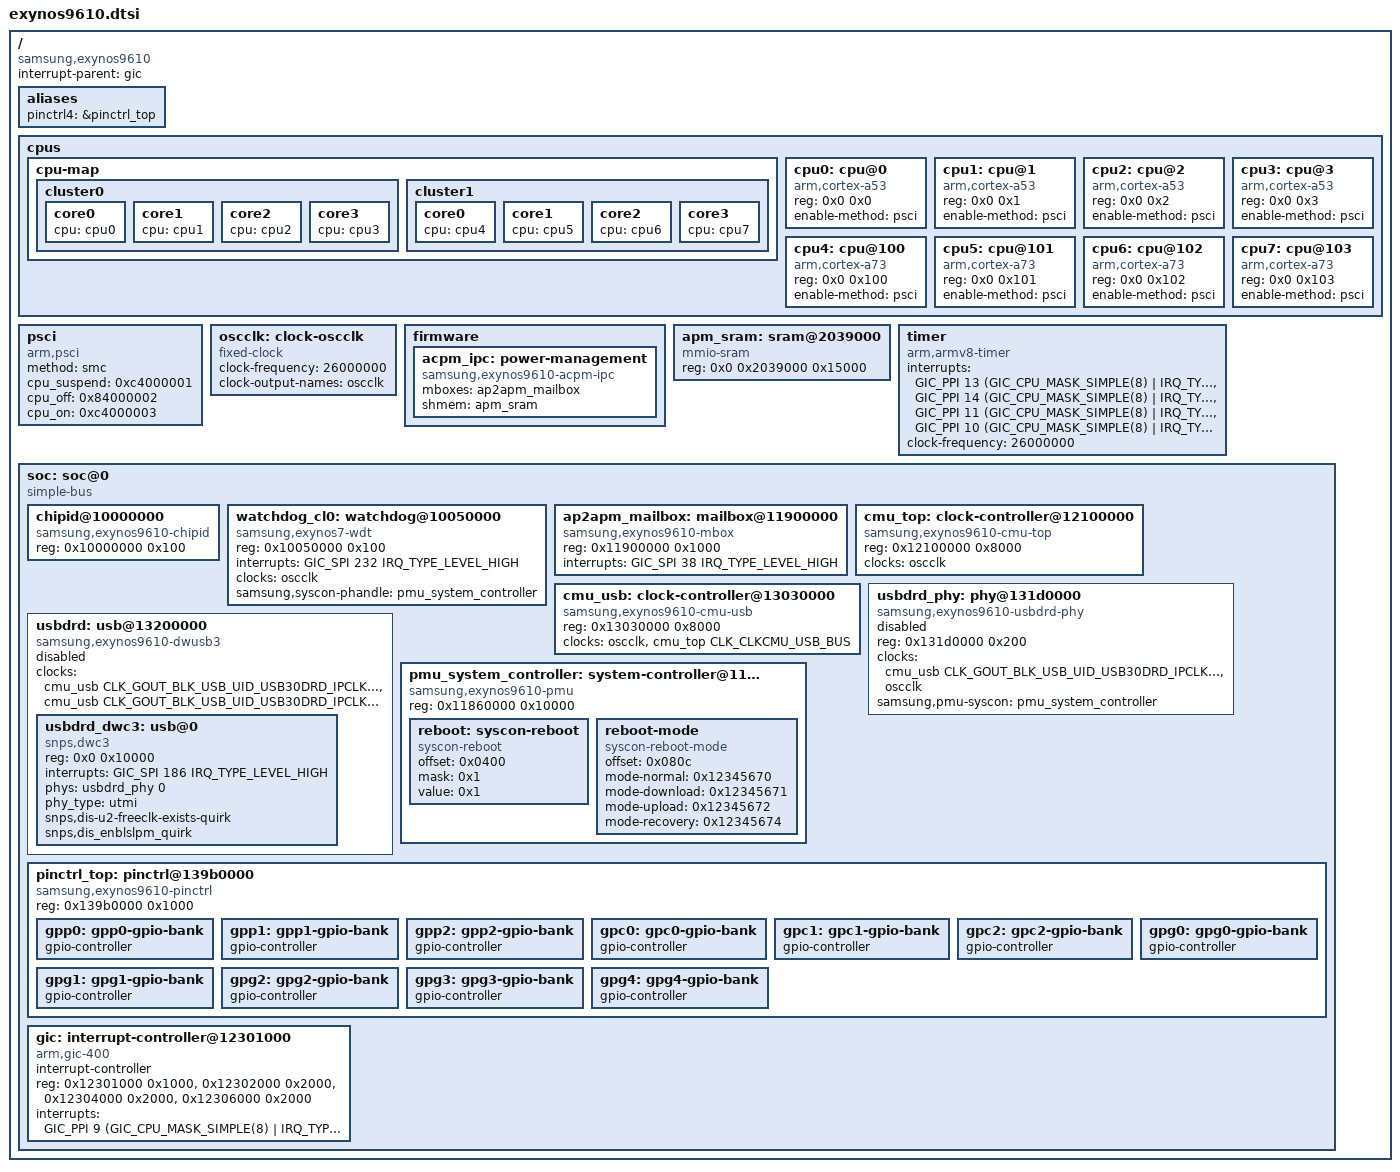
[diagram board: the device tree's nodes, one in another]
// SPDX-License-Identifier: GPL-2.0
/*
 * Samsung Exynos 9610 / 9611 SoC device tree source
 *
 * Early bring-up: CPUs, GIC, timer, PMU (reboot, reboot mode), the CPUCL0
 * watchdog (on the fixed 26 MHz OSCCLK) and USB with the CMU_TOP/CMU_USB
 * clocks it needs.
 */

#include <dt-bindings/clock/samsung,exynos9610-cmu.h>
#include <dt-bindings/interrupt-controller/arm-gic.h>

/ {
	compatible = "samsung,exynos9610";
	#address-cells = <2>;
	#size-cells = <1>;

	interrupt-parent = <&gic>;

	aliases {
		pinctrl4 = &pinctrl_top;
	};

	cpus {
		#address-cells = <2>;
		#size-cells = <0>;

		cpu-map {
			cluster0 {
				core0 {
					cpu = <&cpu0>;
				};
				core1 {
					cpu = <&cpu1>;
				};
				core2 {
					cpu = <&cpu2>;
				};
				core3 {
					cpu = <&cpu3>;
				};
			};

			cluster1 {
				core0 {
					cpu = <&cpu4>;
				};
				core1 {
					cpu = <&cpu5>;
				};
				core2 {
					cpu = <&cpu6>;
				};
				core3 {
					cpu = <&cpu7>;
				};
			};
		};

		cpu0: cpu@0 {
			device_type = "cpu";
			compatible = "arm,cortex-a53";
			reg = <0x0 0x0>;
			enable-method = "psci";
		};

		cpu1: cpu@1 {
			device_type = "cpu";
			compatible = "arm,cortex-a53";
			reg = <0x0 0x1>;
			enable-method = "psci";
		};

		cpu2: cpu@2 {
			device_type = "cpu";
			compatible = "arm,cortex-a53";
			reg = <0x0 0x2>;
			enable-method = "psci";
		};

		cpu3: cpu@3 {
			device_type = "cpu";
			compatible = "arm,cortex-a53";
			reg = <0x0 0x3>;
			enable-method = "psci";
		};

		cpu4: cpu@100 {
			device_type = "cpu";
			compatible = "arm,cortex-a73";
			reg = <0x0 0x100>;
			enable-method = "psci";
		};

		cpu5: cpu@101 {
			device_type = "cpu";
			compatible = "arm,cortex-a73";
			reg = <0x0 0x101>;
			enable-method = "psci";
		};

		cpu6: cpu@102 {
			device_type = "cpu";
			compatible = "arm,cortex-a73";
			reg = <0x0 0x102>;
			enable-method = "psci";
		};

		cpu7: cpu@103 {
			device_type = "cpu";
			compatible = "arm,cortex-a73";
			reg = <0x0 0x103>;
			enable-method = "psci";
		};
	};

	/* Function IDs as in the downstream kernel; firmware is PSCI 0.1 style */
	psci {
		compatible = "arm,psci";
		method = "smc";
		cpu_suspend = <0xc4000001>;
		cpu_off = <0x84000002>;
		cpu_on = <0xc4000003>;
	};

	oscclk: clock-oscclk {
		compatible = "fixed-clock";
		#clock-cells = <0>;
		clock-frequency = <26000000>;
		clock-output-names = "oscclk";
	};

	firmware {
		/* APM firmware: owns the SPEEDY bus of the S2MPU09 PMIC */
		acpm_ipc: power-management {
			compatible = "samsung,exynos9610-acpm-ipc";
			mboxes = <&ap2apm_mailbox>;
			shmem = <&apm_sram>;
		};
	};

	apm_sram: sram@2039000 {
		compatible = "mmio-sram";
		reg = <0x0 0x2039000 0x15000>;
		#address-cells = <1>;
		#size-cells = <1>;
		ranges = <0x0 0x0 0x2039000 0x15000>;
	};

	timer {
		compatible = "arm,armv8-timer";
		interrupts = <GIC_PPI 13 (GIC_CPU_MASK_SIMPLE(8) | IRQ_TYPE_LEVEL_LOW)>,
			     <GIC_PPI 14 (GIC_CPU_MASK_SIMPLE(8) | IRQ_TYPE_LEVEL_LOW)>,
			     <GIC_PPI 11 (GIC_CPU_MASK_SIMPLE(8) | IRQ_TYPE_LEVEL_LOW)>,
			     <GIC_PPI 10 (GIC_CPU_MASK_SIMPLE(8) | IRQ_TYPE_LEVEL_LOW)>;
		clock-frequency = <26000000>;
	};

	soc: soc@0 {
		compatible = "simple-bus";
		#address-cells = <1>;
		#size-cells = <1>;
		ranges = <0x0 0x0 0x0 0x20000000>;

		chipid@10000000 {
			compatible = "samsung,exynos9610-chipid",
				     "samsung,exynos850-chipid";
			reg = <0x10000000 0x100>;
		};

		watchdog_cl0: watchdog@10050000 {
			compatible = "samsung,exynos7-wdt";
			reg = <0x10050000 0x100>;
			interrupts = <GIC_SPI 232 IRQ_TYPE_LEVEL_HIGH>;
			clocks = <&oscclk>;
			clock-names = "watchdog";
			samsung,syscon-phandle = <&pmu_system_controller>;
		};

		ap2apm_mailbox: mailbox@11900000 {
			compatible = "samsung,exynos9610-mbox";
			reg = <0x11900000 0x1000>;
			interrupts = <GIC_SPI 38 IRQ_TYPE_LEVEL_HIGH>;
			#mbox-cells = <0>;
		};

		cmu_top: clock-controller@12100000 {
			compatible = "samsung,exynos9610-cmu-top";
			reg = <0x12100000 0x8000>;
			#clock-cells = <1>;

			clocks = <&oscclk>;
			clock-names = "oscclk";
		};

		cmu_usb: clock-controller@13030000 {
			compatible = "samsung,exynos9610-cmu-usb";
			reg = <0x13030000 0x8000>;
			#clock-cells = <1>;

			clocks = <&oscclk>, <&cmu_top CLK_CLKCMU_USB_BUS>;
			clock-names = "oscclk", "bus";
		};

		usbdrd_phy: phy@131d0000 {
			compatible = "samsung,exynos9610-usbdrd-phy";
			reg = <0x131d0000 0x200>;
			clocks = <&cmu_usb CLK_GOUT_BLK_USB_UID_USB30DRD_IPCLKPORT_ACLK_PHYCTRL_20>,
				 <&oscclk>;
			clock-names = "phy", "ref";
			samsung,pmu-syscon = <&pmu_system_controller>;
			#phy-cells = <1>;
			status = "disabled";
		};

		usbdrd: usb@13200000 {
			compatible = "samsung,exynos9610-dwusb3",
				     "samsung,exynos850-dwusb3";
			ranges = <0x0 0x13200000 0x10000>;
			clocks = <&cmu_usb CLK_GOUT_BLK_USB_UID_USB30DRD_IPCLKPORT_BUS_CLK_EARLY>,
				 <&cmu_usb CLK_GOUT_BLK_USB_UID_USB30DRD_IPCLKPORT_USB30DRD_REF_CLK>;
			clock-names = "bus_early", "ref";
			#address-cells = <1>;
			#size-cells = <1>;
			status = "disabled";

			usbdrd_dwc3: usb@0 {
				compatible = "snps,dwc3";
				reg = <0x0 0x10000>;
				interrupts = <GIC_SPI 186 IRQ_TYPE_LEVEL_HIGH>;
				phys = <&usbdrd_phy 0>;
				phy-names = "usb2-phy";
				/* 8-bit UTMI+, as the stock kernel runs it (GUSB2PHYCFG) */
				phy_type = "utmi";
				snps,dis-u2-freeclk-exists-quirk;
				/* stock runs GUSB2PHYCFG.ENBLSLPM = 0 */
				snps,dis_enblslpm_quirk;
			};
		};

		pmu_system_controller: system-controller@11860000 {
			compatible = "samsung,exynos9610-pmu",
				     "samsung,exynos850-pmu", "syscon";
			reg = <0x11860000 0x10000>;

			reboot: syscon-reboot {
				compatible = "syscon-reboot";
				offset = <0x0400>; /* SWRESET */
				mask = <0x1>;
				value = <0x1>;
			};

			reboot-mode {
				compatible = "syscon-reboot-mode";
				offset = <0x080c>; /* INFORM3 */
				mode-normal = <0x12345670>;
				mode-download = <0x12345671>;
				mode-upload = <0x12345672>;
				mode-recovery = <0x12345674>;
			};
		};

		pinctrl_top: pinctrl@139b0000 {
			compatible = "samsung,exynos9610-pinctrl";
			reg = <0x139b0000 0x1000>;

			gpp0: gpp0-gpio-bank {
				gpio-controller;
				#gpio-cells = <2>;
			};

			gpp1: gpp1-gpio-bank {
				gpio-controller;
				#gpio-cells = <2>;
			};

			gpp2: gpp2-gpio-bank {
				gpio-controller;
				#gpio-cells = <2>;
			};

			gpc0: gpc0-gpio-bank {
				gpio-controller;
				#gpio-cells = <2>;
			};

			gpc1: gpc1-gpio-bank {
				gpio-controller;
				#gpio-cells = <2>;
			};

			gpc2: gpc2-gpio-bank {
				gpio-controller;
				#gpio-cells = <2>;
			};

			gpg0: gpg0-gpio-bank {
				gpio-controller;
				#gpio-cells = <2>;
			};

			gpg1: gpg1-gpio-bank {
				gpio-controller;
				#gpio-cells = <2>;
			};

			gpg2: gpg2-gpio-bank {
				gpio-controller;
				#gpio-cells = <2>;
			};

			gpg3: gpg3-gpio-bank {
				gpio-controller;
				#gpio-cells = <2>;
			};

			gpg4: gpg4-gpio-bank {
				gpio-controller;
				#gpio-cells = <2>;
			};
		};

		gic: interrupt-controller@12301000 {
			compatible = "arm,gic-400";
			#interrupt-cells = <3>;
			#address-cells = <0>;
			interrupt-controller;
			reg = <0x12301000 0x1000>,
			      <0x12302000 0x2000>,
			      <0x12304000 0x2000>,
			      <0x12306000 0x2000>;
			interrupts = <GIC_PPI 9 (GIC_CPU_MASK_SIMPLE(8) | IRQ_TYPE_LEVEL_HIGH)>;
		};
	};
};
